# MSP430G2X55 register map
Vendor: msp430gen; File version: v0.4.0-16-g4f822b9
Registers are 8-bit, read-write, reset 0x0 unless marked. A register's access mark holds for its fields unless they carry their own. Offsets are from the block's base; lines under a group give offsets from that group; [hi:lo] are bit positions; {n}, {i} and the like mark numbered series; 'fields as' and 'values as' point back to an identical list; <NAME> marks a mode.

## Memory map
0x00000000 SPECIAL_FUNCTION
0x00000010 PORT_3_4
0x00000020 PORT_1_2
0x00000048 ADC10
0x00000052 SYSTEM_CLOCK
0x00000058 COMPARATOR_A
0x0000005C USCI_A0_UART_MODE
0x00000060 USCI_A0_SPI_MODE
0x00000068 USCI_B0_I2C_MODE
0x00000068 USCI_B0_SPI_MODE
0x0000011C TIMER1_A3
0x0000011E TIMER_B3
0x00000120 WATCHDOG_TIMER
0x00000128 FLASH
0x0000012E TIMER0_A3 — Timer A3
0x000010C0 TLV_CALIBRATION_DATA
0x000010F8 CALIBRATION_DATA
0x0000FFE0 _INTERRUPTS

## Interrupts
0 TIMER1_A1 (_INTERRUPTS) — 0xFFE0 Timer1_A CC1-4, TA1
1 TIMER1_A0 (_INTERRUPTS) — 0xFFE2 Timer1_A CC0
2 PORT1 (_INTERRUPTS) — 0xFFE4 Port 1
3 PORT2 (_INTERRUPTS) — 0xFFE6 Port 2
4 TRAPINT (_INTERRUPTS) — 0xFFE8 TRAPINT
5 ADC10 (_INTERRUPTS) — 0xFFEA ADC10
6 USCIAB0TX (_INTERRUPTS) — 0xFFEC USCI A0/B0 Transmit
7 USCIAB0RX (_INTERRUPTS) — 0xFFEE USCI A0/B0 Receive
8 TIMER0_A1 (_INTERRUPTS) — 0xFFF0 Timer0_A CC1, TA0
9 TIMER0_A0 (_INTERRUPTS) — 0xFFF2 Timer0_A CC0
10 WDT (_INTERRUPTS) — 0xFFF4 Watchdog Timer
11 COMPARATORA (_INTERRUPTS) — 0xFFF6 Comparator A
12 TIMERB1 (_INTERRUPTS) — 0xFFF8 Timer B CC1-6, TB
13 TIMERB0 (_INTERRUPTS) — 0xFFFA Timer B CC0
14 NMI (_INTERRUPTS) — 0xFFFC Non-maskable

## SPECIAL_FUNCTION
Base 0x00000000
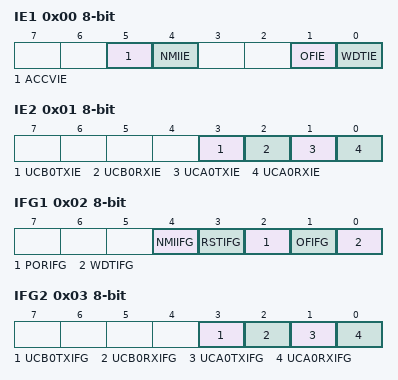
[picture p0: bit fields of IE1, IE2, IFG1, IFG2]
0x00 IE1 — Interrupt Enable 1
  [5] ACCVIE — Flash Access Violation Interrupt Enable
  [4] NMIIE — NMI Interrupt Enable
  [1] OFIE — Osc. Fault Interrupt Enable
  [0] WDTIE — Watchdog Interrupt Enable
0x01 IE2 — Interrupt Enable 2
  [3] UCB0TXIE, [2] UCB0RXIE, [1] UCA0TXIE, [0] UCA0RXIE
0x02 IFG1 — Interrupt Flag 1
  [4] NMIIFG — NMI Interrupt Flag
  [3] RSTIFG — Reset Interrupt Flag
  [2] PORIFG — Power On Interrupt Flag
  [1] OFIFG — Osc. Fault Interrupt Flag
  [0] WDTIFG — Watchdog Interrupt Flag
0x03 IFG2 — Interrupt Flag 2
  [3] UCB0TXIFG, [2] UCB0RXIFG, [1] UCA0TXIFG, [0] UCA0RXIFG

## PORT_3_4
Base 0x00000010
0x00 P3REN — Port 3 Resistor Enable
  [n] P{n} (n=0..7)
  [7:0] P3REN — Port 3 Resistor Enable register
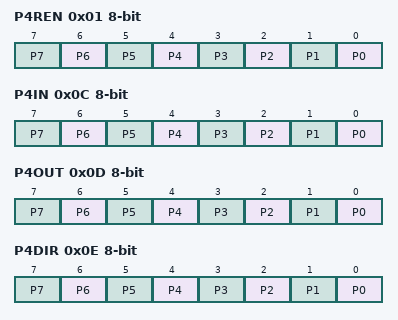
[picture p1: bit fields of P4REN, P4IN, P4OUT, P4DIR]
0x01 P4REN — Port 4 Resistor Enable
  [n] P{n} (n=0..7)
0x08 P3IN — Port 3 Input
  [n] P{n} (n=0..7)
  [7:0] P3IN — Port 3 Input register
0x09 P3OUT — Port 3 Output
  [n] P{n} (n=0..7)
  [7:0] P3OUT — Port 3 Output register
0x0A P3DIR — Port 3 Direction
  [n] P{n} (n=0..7)
  [7:0] P3DIR — Port 3 Direction register
0x0B P3SEL — Port 3 Selection
  [n] P{n} (n=0..7)
  [7:0] P3SEL — Port 3 Selection register
0x0C P4IN — Port 4 Input
  [n] P{n} (n=0..7)
0x0D P4OUT — Port 4 Output
  [n] P{n} (n=0..7)
0x0E P4DIR — Port 4 Direction
  [n] P{n} (n=0..7)
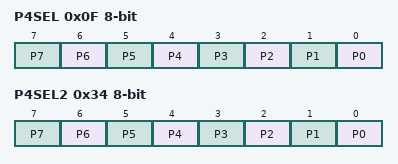
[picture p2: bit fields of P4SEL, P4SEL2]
0x0F P4SEL — Port 4 Selection
  [n] P{n} (n=0..7)
0x33 P3SEL2 — Port 3 Selection 2
  [n] P{n} (n=0..7)
  [7:0] P3SEL2 — Port 3 Selection register 2
0x34 P4SEL2 — Port 4 Selection 2
  [n] P{n} (n=0..7)

## PORT_1_2
Base 0x00000020
0x00 P1IN — Port 1 Input
  [n] P{n} (n=0..7)
  [7:0] P1IN — Port 1 Input register
0x01 P1OUT — Port 1 Output
  [n] P{n} (n=0..7)
  [7:0] P1OUT — Port 1 Output register
0x02 P1DIR — Port 1 Direction
  [n] P{n} (n=0..7)
  [7:0] P1DIR — Port 1 Direction register
0x03 P1IFG — Port 1 Interrupt Flag
  [n] P{n} (n=0..7)
  [7:0] P1IFG — Port 1 Interrupt Flag register
0x04 P1IES — Port 1 Interrupt Edge Select
  [n] P{n} (n=0..7)
  [7:0] P1IES — Port 1 Interrupt Edge Select register
0x05 P1IE — Port 1 Interrupt Enable
  [n] P{n} (n=0..7)
  [7:0] P1IE — Port 1 Interrupt Enable register
0x06 P1SEL — Port 1 Selection
  [n] P{n} (n=0..7)
  [7:0] P1SEL — Port 1 Selection register
0x07 P1REN — Port 1 Resistor Enable
  [n] P{n} (n=0..7)
  [7:0] P1REN — Port 1 Resistor Enable register
0x08 P2IN — Port 2 Input
  [n] P{n} (n=0..7)
  [7:0] P2IN — Port 2 Input register
0x09 P2OUT — Port 2 Output
  [n] P{n} (n=0..7)
  [7:0] P2OUT — Port 2 Output register
0x0A P2DIR — Port 2 Direction
  [n] P{n} (n=0..7)
  [7:0] P2DIR — Port 2 Direction register
0x0B P2IFG — Port 2 Interrupt Flag
  [n] P{n} (n=0..7)
  [7:0] P2IFG — Port 2 Interrupt Flag register
0x0C P2IES — Port 2 Interrupt Edge Select
  [n] P{n} (n=0..7)
  [7:0] P2IES — Port 2 Interrupt Edge Select register
0x0D P2IE — Port 2 Interrupt Enable
  [n] P{n} (n=0..7)
  [7:0] P2IE — Port 2 Interrupt Enable register
0x0E P2SEL — Port 2 Selection
  [n] P{n} (n=0..7)
  [7:0] P2SEL — Port 2 Selection register
0x0F P2REN — Port 2 Resistor Enable
  [n] P{n} (n=0..7)
  [7:0] P2REN — Port 2 Resistor Enable register
0x21 P1SEL2 — Port 1 Selection 2
  [n] P{n} (n=0..7)
  [7:0] P1SEL2 — Port 1 Selection register 2
0x22 P2SEL2 — Port 2 Selection 2
  [n] P{n} (n=0..7)
  [7:0] P2SEL2 — Port 2 Selection register 2
